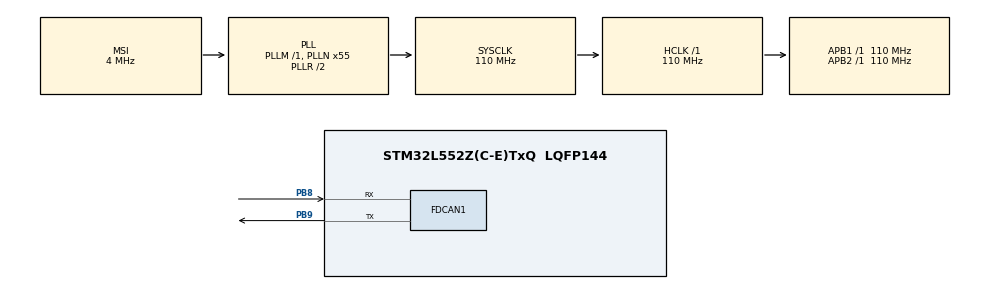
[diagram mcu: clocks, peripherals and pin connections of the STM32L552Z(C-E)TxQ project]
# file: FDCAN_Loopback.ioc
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FDCAN1.AutoRetransmission=ENABLE
FDCAN1.CalculateBaudRateNominal=1374999
FDCAN1.CalculateTimeBitNominal=727
FDCAN1.CalculateTimeQuantumNominal=9.090909090909092
FDCAN1.ClockDivider=FDCAN_CLOCK_DIV1
FDCAN1.DataPrescaler=1
FDCAN1.DataSyncJumpWidth=4
FDCAN1.DataTimeSeg1=5
FDCAN1.DataTimeSeg2=4
FDCAN1.ExtFiltersNbr=1
FDCAN1.FrameFormat=FDCAN_FRAME_FD_BRS
FDCAN1.Mode=FDCAN_MODE_EXTERNAL_LOOPBACK
FDCAN1.NominalPrescaler=1
FDCAN1.NominalSyncJumpWidth=16
FDCAN1.NominalTimeSeg1=63
FDCAN1.NominalTimeSeg2=16
FDCAN1.ProtocolException=DISABLE
FDCAN1.StdFiltersNbr=1
FDCAN1.TransmitPause=ENABLE
FDCAN1.TxFifoQueueMode=FDCAN_TX_FIFO_OPERATION
Mcu.Family=STM32L5
Mcu.Name=STM32L552Z(C-E)TxQ
Mcu.Package=LQFP144
NVIC.PriorityGroup=NVIC_PRIORITYGROUP_3
PB8.GPIO_Speed=GPIO_SPEED_FREQ_VERY_HIGH
PB8.Mode=FDCAN_Activate
PB8.Signal=FDCAN1_RX
PB9.GPIO_Speed=GPIO_SPEED_FREQ_VERY_HIGH
PB9.Mode=FDCAN_Activate
PB9.Signal=FDCAN1_TX
ProjectManager.HeapSize=0x200
ProjectManager.StackSize=0x400
ProjectManager.TargetToolchain=EWARM V8.32
RCC.ADCCLockSelection=RCC_ADCCLKSOURCE_SYSCLK
RCC.ADCFreq_Value=110000000
RCC.AHBFreq_Value=110000000
RCC.APB1Freq_Value=110000000
RCC.APB1TimFreq_Value=110000000
RCC.APB2Freq_Value=110000000
RCC.APB2TimFreq_Value=110000000
RCC.CK48CLockSelection=RCC_USBCLKSOURCE_MSI
RCC.CortexFreq_Value=110000000
RCC.DATA_CACHE_ENABLE=0
RCC.HCLKFreq_Value=110000000
RCC.HSE_VALUE=16000000
RCC.HSI48_VALUE=48000000
RCC.HSI_VALUE=16000000
RCC.INSTRUCTION_CACHE_ENABLE=0
RCC.LSE_VALUE=32768
RCC.MSI_VALUE=4000000
RCC.PLLN=55
RCC.SYSCLKFreq_VALUE=110000000
RCC.SYSCLKSource=RCC_SYSCLKSOURCE_PLLCLK
RCC.USBFreq_Value=4000000
RCC.VCOOutputFreq_Value=220000000
VP_ICACHE_VS_ICACHE.Mode=DirectMappedCache
VP_PWR_VS_DBSignals.Mode=DisableDeadBatterySignals
board=custom

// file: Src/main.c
/* USER CODE BEGIN Header */
/**
  ******************************************************************************
  * @file    FDCAN/FDCAN_Loopback/Src/main.c
  * @author  MCD Application Team
  * @brief   This sample code shows how to configure the FDCAN peripheral to
  *          operate in loopback mode.
  ******************************************************************************
  * @attention
  *
  * Copyright (c) 2019 STMicroelectronics.
  * All rights reserved.
  *
  * This software is licensed under terms that can be found in the LICENSE file
  * in the root directory of this software component.
  * If no LICENSE file comes with this software, it is provided AS-IS.
  *
  ******************************************************************************
  */
/* USER CODE END Header */
#include "main.h"

FDCAN_HandleTypeDef hfdcan1;

/* USER CODE BEGIN PV */
FDCAN_FilterTypeDef sFilterConfig;
FDCAN_TxHeaderTypeDef TxHeader;
FDCAN_RxHeaderTypeDef RxHeader;
uint8_t TxData0[] = {0x10, 0x32, 0x54, 0x76, 0x98, 0x00, 0x11, 0x22, 0x33, 0x44, 0x55, 0x66};
uint8_t TxData1[] = {0x55, 0x55, 0x55, 0x55, 0x55, 0x55, 0x55, 0x55, 0x55, 0x55, 0x55, 0x55};
uint8_t TxData2[] = {0xFF, 0x00, 0xFF, 0x00, 0xFF, 0x00, 0xFF, 0x00, 0xFF, 0x00, 0xFF, 0x00};
uint8_t RxData[12];

/* USER CODE END PV */

void SystemClock_Config(void);
static void MX_GPIO_Init(void);
static void MX_ICACHE_Init(void);
static void MX_FDCAN1_Init(void);
/* USER CODE BEGIN PFP */
static uint32_t BufferCmp8b(uint8_t* pBuffer1, uint8_t* pBuffer2, uint16_t BufferLength);

/* USER CODE END PFP */

int main(void)
{
  /* USER CODE BEGIN 1 */

  /* STM32L5xx HAL library initialization:
       - Systick timer is configured by default as source of time base, but user
         can eventually implement his proper time base source (a general purpose
         timer for example or other time source), keeping in mind that Time base
         duration should be kept 1ms since PPP_TIMEOUT_VALUEs are defined and
         handled in milliseconds basis.
       - Set NVIC Group Priority to 3
       - Low Level Initialization
     */
  /* USER CODE END 1 */

  /* MCU Configuration--------------------------------------------------------*/

  /* Reset of all peripherals, Initializes the Flash interface and the Systick. */
  HAL_Init();

  /* USER CODE BEGIN Init */
  /* Configure LED4 and LED5 */
  BSP_LED_Init(LED4);
  BSP_LED_Init(LED5);
  /* USER CODE END Init */

  /* Configure the system clock */
  SystemClock_Config();

  /* Initialize all configured peripherals */
  MX_GPIO_Init();
  MX_ICACHE_Init();
  MX_FDCAN1_Init();
  /* USER CODE BEGIN 2 */

  /*##-1 Configure the FDCAN filters ########################################*/
  /* Configure standard ID reception filter to Rx FIFO 0 */
  sFilterConfig.IdType = FDCAN_STANDARD_ID;
  sFilterConfig.FilterIndex = 0;
  sFilterConfig.FilterType = FDCAN_FILTER_DUAL;
  sFilterConfig.FilterConfig = FDCAN_FILTER_TO_RXFIFO0;
  sFilterConfig.FilterID1 = 0x444;
  sFilterConfig.FilterID2 = 0x555;
  if (HAL_FDCAN_ConfigFilter(&hfdcan1, &sFilterConfig) != HAL_OK)
  {
    Error_Handler();
  }

  /* Configure extended ID reception filter to Rx FIFO 1 */
  sFilterConfig.IdType = FDCAN_EXTENDED_ID;
  sFilterConfig.FilterIndex = 0;
  sFilterConfig.FilterType = FDCAN_FILTER_RANGE_NO_EIDM;
  sFilterConfig.FilterConfig = FDCAN_FILTER_TO_RXFIFO1;
  sFilterConfig.FilterID1 = 0x1111111;
  sFilterConfig.FilterID2 = 0x2222222;
  if (HAL_FDCAN_ConfigFilter(&hfdcan1, &sFilterConfig) != HAL_OK)
  {
    Error_Handler();
  }

  /* Configure global filter:
     Filter all remote frames with STD and EXT ID
     Reject non matching frames with STD ID and EXT ID */
  if (HAL_FDCAN_ConfigGlobalFilter(&hfdcan1, FDCAN_REJECT, FDCAN_REJECT, FDCAN_FILTER_REMOTE, FDCAN_FILTER_REMOTE) != HAL_OK)
  {
    Error_Handler();
  }

  /*##-2 Start FDCAN controller (continuous listening CAN bus) ##############*/
  if (HAL_FDCAN_Start(&hfdcan1) != HAL_OK)
  {
    Error_Handler();
  }

  /*##-3 Transmit messages ##################################################*/
  /* Add message to Tx FIFO */
  TxHeader.Identifier = 0x444;
  TxHeader.IdType = FDCAN_STANDARD_ID;
  TxHeader.TxFrameType = FDCAN_DATA_FRAME;
  TxHeader.DataLength = FDCAN_DLC_BYTES_12;
  TxHeader.ErrorStateIndicator = FDCAN_ESI_ACTIVE;
  TxHeader.BitRateSwitch = FDCAN_BRS_ON;
  TxHeader.FDFormat = FDCAN_FD_CAN;
  TxHeader.TxEventFifoControl = FDCAN_STORE_TX_EVENTS;
  TxHeader.MessageMarker = 0x52;
  if (HAL_FDCAN_AddMessageToTxFifoQ(&hfdcan1, &TxHeader, TxData0) != HAL_OK)
  {
    Error_Handler();
  }

  /* Add second message to Tx FIFO */
  TxHeader.Identifier = 0x1111112;
  TxHeader.IdType = FDCAN_EXTENDED_ID;
  TxHeader.TxFrameType = FDCAN_DATA_FRAME;
  TxHeader.DataLength = FDCAN_DLC_BYTES_12;
  TxHeader.ErrorStateIndicator = FDCAN_ESI_PASSIVE;
  TxHeader.BitRateSwitch = FDCAN_BRS_ON;
  TxHeader.FDFormat = FDCAN_FD_CAN;
  TxHeader.TxEventFifoControl = FDCAN_STORE_TX_EVENTS;
  TxHeader.MessageMarker = 0xCC;
  if (HAL_FDCAN_AddMessageToTxFifoQ(&hfdcan1, &TxHeader, TxData1) != HAL_OK)
  {
    Error_Handler();
  }

  /* Add third message to Tx FIFO */
  TxHeader.Identifier = 0x1111113;
  TxHeader.IdType = FDCAN_EXTENDED_ID;
  TxHeader.TxFrameType = FDCAN_DATA_FRAME;
  TxHeader.DataLength = FDCAN_DLC_BYTES_12;
  TxHeader.ErrorStateIndicator = FDCAN_ESI_PASSIVE;
  TxHeader.BitRateSwitch = FDCAN_BRS_OFF;
  TxHeader.FDFormat = FDCAN_FD_CAN;
  TxHeader.TxEventFifoControl = FDCAN_STORE_TX_EVENTS;
  TxHeader.MessageMarker = 0xDD;
  if (HAL_FDCAN_AddMessageToTxFifoQ(&hfdcan1, &TxHeader, TxData2) != HAL_OK)
  {
    Error_Handler();
  }

  /* Wait transmissions complete */
  while (HAL_FDCAN_GetTxFifoFreeLevel(&hfdcan1) != 3) {}

  /*##-4 Receive messages ###################################################*/
  /* Check one message is received in Rx FIFO 0 */
  if(HAL_FDCAN_GetRxFifoFillLevel(&hfdcan1, FDCAN_RX_FIFO0) != 1)
  {
    Error_Handler();
  }

  /* Retrieve message from Rx FIFO 0 */
  if (HAL_FDCAN_GetRxMessage(&hfdcan1, FDCAN_RX_FIFO0, &RxHeader, RxData) != HAL_OK)
  {
    Error_Handler();
  }

  /* Compare payload to expected data */
  if (BufferCmp8b(TxData0, RxData, 12) != 0)
  {
    Error_Handler();
  }

  /* Check two messages are received in Rx FIFO 1 */
  if(HAL_FDCAN_GetRxFifoFillLevel(&hfdcan1, FDCAN_RX_FIFO1) != 2)
  {
    Error_Handler();
  }

  /* Retrieve message from Rx FIFO 1 */
  if (HAL_FDCAN_GetRxMessage(&hfdcan1, FDCAN_RX_FIFO1, &RxHeader, RxData) != HAL_OK)
  {
    Error_Handler();
  }

  /* Compare payload to expected data */
  if (BufferCmp8b(TxData1, RxData, 12) != 0)
  {
    Error_Handler();
  }

  /* Retrieve next message from Rx FIFO 1 */
  if (HAL_FDCAN_GetRxMessage(&hfdcan1, FDCAN_RX_FIFO1, &RxHeader, RxData) != HAL_OK)
  {
    Error_Handler();
  }

  /* Compare payload to expected data */
  if (BufferCmp8b(TxData2, RxData, 12) != 0)
  {
    Error_Handler();
  }
  /* USER CODE END 2 */

  /* Infinite loop */
  /* USER CODE BEGIN WHILE */
  while (1)
  {
    /* Toggle LED4 */
    BSP_LED_Toggle(LED4);
    HAL_Delay(100);
    /* USER CODE END WHILE */

  }
}

void SystemClock_Config(void)
{
  RCC_OscInitTypeDef RCC_OscInitStruct = {0};
  RCC_ClkInitTypeDef RCC_ClkInitStruct = {0};

  /** Configure the main internal regulator output voltage
  */
  if (HAL_PWREx_ControlVoltageScaling(PWR_REGULATOR_VOLTAGE_SCALE0) != HAL_OK)
  {
    Error_Handler();
  }

  /** Initializes the RCC Oscillators according to the specified parameters
  * in the RCC_OscInitTypeDef structure.
  */
  RCC_OscInitStruct.OscillatorType = RCC_OSCILLATORTYPE_MSI;
  RCC_OscInitStruct.MSIState = RCC_MSI_ON;
  RCC_OscInitStruct.MSICalibrationValue = RCC_MSICALIBRATION_DEFAULT;
  RCC_OscInitStruct.MSIClockRange = RCC_MSIRANGE_6;
  RCC_OscInitStruct.PLL.PLLState = RCC_PLL_ON;
  RCC_OscInitStruct.PLL.PLLSource = RCC_PLLSOURCE_MSI;
  RCC_OscInitStruct.PLL.PLLM = 1;
  RCC_OscInitStruct.PLL.PLLN = 55;
  RCC_OscInitStruct.PLL.PLLP = RCC_PLLP_DIV7;
  RCC_OscInitStruct.PLL.PLLQ = RCC_PLLQ_DIV2;
  RCC_OscInitStruct.PLL.PLLR = RCC_PLLR_DIV2;
  if (HAL_RCC_OscConfig(&RCC_OscInitStruct) != HAL_OK)
  {
    Error_Handler();
  }

  /** Initializes the CPU, AHB and APB buses clocks
  */
  RCC_ClkInitStruct.ClockType = RCC_CLOCKTYPE_HCLK|RCC_CLOCKTYPE_SYSCLK
                              |RCC_CLOCKTYPE_PCLK1|RCC_CLOCKTYPE_PCLK2;
  RCC_ClkInitStruct.SYSCLKSource = RCC_SYSCLKSOURCE_PLLCLK;
  RCC_ClkInitStruct.AHBCLKDivider = RCC_SYSCLK_DIV1;
  RCC_ClkInitStruct.APB1CLKDivider = RCC_HCLK_DIV1;
  RCC_ClkInitStruct.APB2CLKDivider = RCC_HCLK_DIV1;

  if (HAL_RCC_ClockConfig(&RCC_ClkInitStruct, FLASH_LATENCY_5) != HAL_OK)
  {
    Error_Handler();
  }
}

static void MX_FDCAN1_Init(void)
{

  hfdcan1.Instance = FDCAN1;
  hfdcan1.Init.ClockDivider = FDCAN_CLOCK_DIV1;
  hfdcan1.Init.FrameFormat = FDCAN_FRAME_FD_BRS;
  hfdcan1.Init.Mode = FDCAN_MODE_EXTERNAL_LOOPBACK;
  hfdcan1.Init.AutoRetransmission = ENABLE;
  hfdcan1.Init.TransmitPause = ENABLE;
  hfdcan1.Init.ProtocolException = DISABLE;
  hfdcan1.Init.NominalPrescaler = 1;
  hfdcan1.Init.NominalSyncJumpWidth = 16;
  hfdcan1.Init.NominalTimeSeg1 = 63;
  hfdcan1.Init.NominalTimeSeg2 = 16;
  hfdcan1.Init.DataPrescaler = 1;
  hfdcan1.Init.DataSyncJumpWidth = 4;
  hfdcan1.Init.DataTimeSeg1 = 5;
  hfdcan1.Init.DataTimeSeg2 = 4;
  hfdcan1.Init.StdFiltersNbr = 1;
  hfdcan1.Init.ExtFiltersNbr = 1;
  hfdcan1.Init.TxFifoQueueMode = FDCAN_TX_FIFO_OPERATION;
  if (HAL_FDCAN_Init(&hfdcan1) != HAL_OK)
  {
    Error_Handler();
  }

}

static void MX_ICACHE_Init(void)
{

  /** Enable instruction cache in 1-way (direct mapped cache)
  */
  if (HAL_ICACHE_ConfigAssociativityMode(ICACHE_1WAY) != HAL_OK)
  {
    Error_Handler();
  }
  if (HAL_ICACHE_Enable() != HAL_OK)
  {
    Error_Handler();
  }

}

static void MX_GPIO_Init(void)
{

  /* GPIO Ports Clock Enable */
  __HAL_RCC_GPIOB_CLK_ENABLE();

}

/* USER CODE BEGIN 4 */

/**
  * @brief Compares two buffers.
  * @par Input
  *  - pBuffer1, pBuffer2: buffers to be compared.
  *  - BufferLength: buffer's length
  * @par Output
  * None.
  * @retval
  *   0: pBuffer1 identical to pBuffer2
  *   1: pBuffer1 differs from pBuffer2
  */
static uint32_t BufferCmp8b(uint8_t* pBuffer1, uint8_t* pBuffer2, uint16_t BufferLength)
{
  while(BufferLength--)
  {
    if(*pBuffer1 != *pBuffer2)
    {
      return 1;
    }

    pBuffer1++;
    pBuffer2++;
  }
  return 0;
}
/* USER CODE END 4 */

void Error_Handler(void)
{
  /* USER CODE BEGIN Error_Handler_Debug */
  /* User can add his own implementation to report the HAL error return state */
  /* Turn LED5 on */
  BSP_LED_On(LED5);

  while(1)
  {
  }
  /* USER CODE END Error_Handler_Debug */
}
